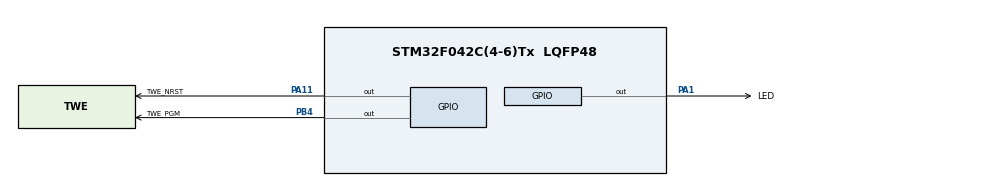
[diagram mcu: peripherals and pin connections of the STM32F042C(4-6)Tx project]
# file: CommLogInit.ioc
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Mcu.Family=STM32F0
Mcu.Name=STM32F042C(4-6)Tx
Mcu.Package=LQFP48
PA1.GPIO_Label=LED
PA1.Signal=GPIO_Output
PA11.GPIO_Label=TWE_NRST
PA11.Signal=GPIO_Output
PB4.GPIO_Label=TWE_PGM
PB4.Signal=GPIO_Output
ProjectManager.HeapSize=0x200
ProjectManager.StackSize=0x400
ProjectManager.TargetToolchain=STM32CubeIDE
board=custom

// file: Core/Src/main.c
/* USER CODE BEGIN Header */
/**
  ******************************************************************************
  * @file           : main.c
  * @brief          : Main program body
  ******************************************************************************
  * @attention
  *
  * <h2><center>&copy; Copyright (c) 2020 STMicroelectronics.
  * All rights reserved.</center></h2>
  *
  * This software component is licensed by ST under BSD 3-Clause license,
  * the "License"; You may not use this file except in compliance with the
  * License. You may obtain a copy of the License at:
  *                        opensource.org/licenses/BSD-3-Clause
  *
  ******************************************************************************
  */
/* USER CODE END Header */
#include "main.h"

void SystemClock_Config(void);
static void MX_GPIO_Init(void);

/* USER CODE BEGIN 0 */

//#define PGM

/* USER CODE END 0 */

int main(void)
{

  /* MCU Configuration--------------------------------------------------------*/

  /* Reset of all peripherals, Initializes the Flash interface and the Systick. */
  HAL_Init();

  /* Configure the system clock */
  SystemClock_Config();

  /* Initialize all configured peripherals */
  MX_GPIO_Init();
  /* USER CODE BEGIN 2 */

  // Reset TWELITE

  HAL_GPIO_WritePin(LED_GPIO_Port, LED_Pin, GPIO_PIN_RESET);

  HAL_GPIO_WritePin(TWE_PGM_GPIO_Port, TWE_PGM_Pin, GPIO_PIN_SET);

#ifdef PGM
	  HAL_GPIO_WritePin(TWE_PGM_GPIO_Port, TWE_PGM_Pin, GPIO_PIN_RESET);
	  HAL_Delay(100);
#endif
  HAL_GPIO_WritePin(TWE_NRST_GPIO_Port, TWE_NRST_Pin, GPIO_PIN_RESET);
  HAL_Delay(100);
  HAL_GPIO_WritePin(TWE_NRST_GPIO_Port, TWE_NRST_Pin, GPIO_PIN_SET);

#ifdef PGM
	  HAL_Delay(100);
	  HAL_GPIO_WritePin(TWE_PGM_GPIO_Port, TWE_PGM_Pin, GPIO_PIN_SET);
#endif

  HAL_GPIO_WritePin(LED_GPIO_Port, LED_Pin, GPIO_PIN_SET);

  /* USER CODE END 2 */

  /* Infinite loop */
  while (1)
  {

  }
}

void SystemClock_Config(void)
{
  RCC_OscInitTypeDef RCC_OscInitStruct = {0};
  RCC_ClkInitTypeDef RCC_ClkInitStruct = {0};

  /** Initializes the RCC Oscillators according to the specified parameters
  * in the RCC_OscInitTypeDef structure.
  */
  RCC_OscInitStruct.OscillatorType = RCC_OSCILLATORTYPE_HSI;
  RCC_OscInitStruct.HSIState = RCC_HSI_ON;
  RCC_OscInitStruct.HSICalibrationValue = RCC_HSICALIBRATION_DEFAULT;
  RCC_OscInitStruct.PLL.PLLState = RCC_PLL_NONE;
  if (HAL_RCC_OscConfig(&RCC_OscInitStruct) != HAL_OK)
  {
    Error_Handler();
  }

  /** Initializes the CPU, AHB and APB buses clocks
  */
  RCC_ClkInitStruct.ClockType = RCC_CLOCKTYPE_HCLK|RCC_CLOCKTYPE_SYSCLK
                              |RCC_CLOCKTYPE_PCLK1;
  RCC_ClkInitStruct.SYSCLKSource = RCC_SYSCLKSOURCE_HSI;
  RCC_ClkInitStruct.AHBCLKDivider = RCC_SYSCLK_DIV1;
  RCC_ClkInitStruct.APB1CLKDivider = RCC_HCLK_DIV1;

  if (HAL_RCC_ClockConfig(&RCC_ClkInitStruct, FLASH_LATENCY_0) != HAL_OK)
  {
    Error_Handler();
  }
}

static void MX_GPIO_Init(void)
{
  GPIO_InitTypeDef GPIO_InitStruct = {0};

  /* GPIO Ports Clock Enable */
  __HAL_RCC_GPIOA_CLK_ENABLE();
  __HAL_RCC_GPIOB_CLK_ENABLE();

  /*Configure GPIO pin Output Level */
  HAL_GPIO_WritePin(GPIOA, LED_Pin|TWE_NRST_Pin, GPIO_PIN_RESET);

  /*Configure GPIO pin Output Level */
  HAL_GPIO_WritePin(TWE_PGM_GPIO_Port, TWE_PGM_Pin, GPIO_PIN_RESET);

  /*Configure GPIO pins : LED_Pin TWE_NRST_Pin */
  GPIO_InitStruct.Pin = LED_Pin|TWE_NRST_Pin;
  GPIO_InitStruct.Mode = GPIO_MODE_OUTPUT_PP;
  GPIO_InitStruct.Pull = GPIO_NOPULL;
  GPIO_InitStruct.Speed = GPIO_SPEED_FREQ_LOW;
  HAL_GPIO_Init(GPIOA, &GPIO_InitStruct);

  /*Configure GPIO pin : TWE_PGM_Pin */
  GPIO_InitStruct.Pin = TWE_PGM_Pin;
  GPIO_InitStruct.Mode = GPIO_MODE_OUTPUT_PP;
  GPIO_InitStruct.Pull = GPIO_NOPULL;
  GPIO_InitStruct.Speed = GPIO_SPEED_FREQ_LOW;
  HAL_GPIO_Init(TWE_PGM_GPIO_Port, &GPIO_InitStruct);

}

void Error_Handler(void)
{
}
